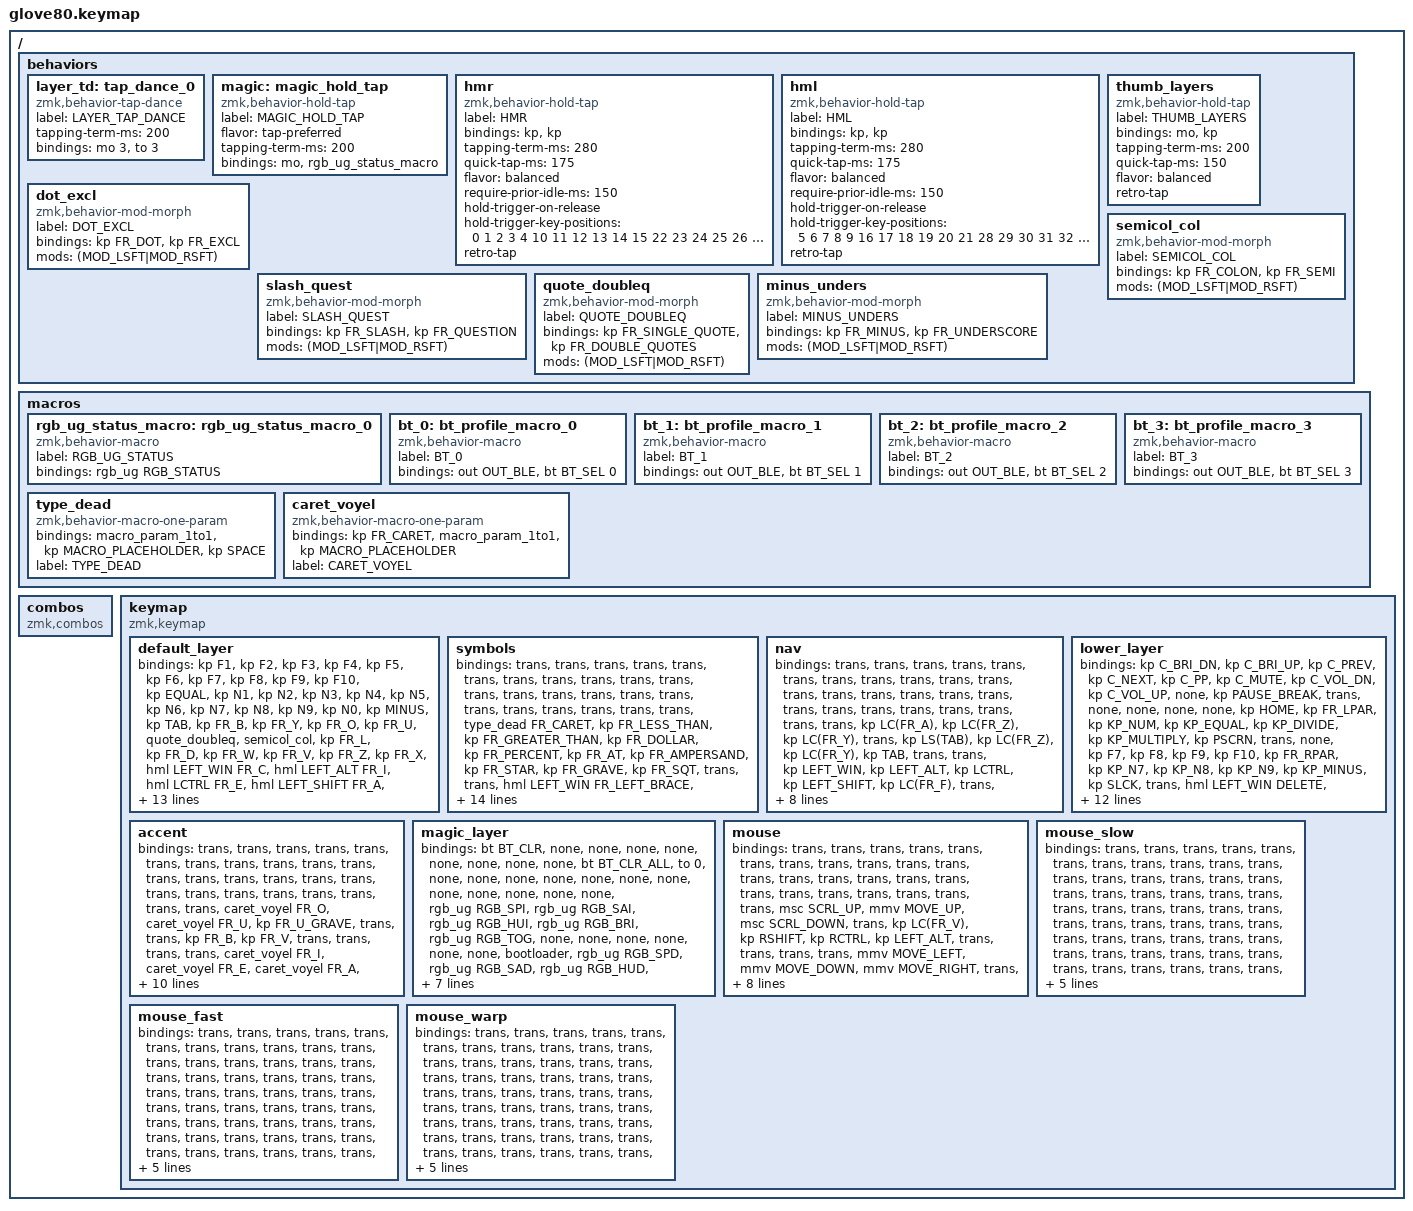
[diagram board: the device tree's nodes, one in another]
/*
 * Copyright (c) 2020 The ZMK Contributors
 *
 * SPDX-License-Identifier: MIT
 */

#include <behaviors.dtsi>
#include <dt-bindings/zmk/bt.h>
#include <dt-bindings/zmk/keys.h>
#include <dt-bindings/zmk/outputs.h>
#include <dt-bindings/zmk/pointing.h>
#include <dt-bindings/zmk/rgb.h>
#include "keys_fr_belgian.h"

#define HYPER LC(LS(LG(LALT)))

// layers

#define DEFAULT 0
#define SYMBOLS  1
#define NAV 2
#define LOWER 3
#define ACCENT 4
#define MAGIC 5
#define MOUSE 6
#define MOUSE_SLOW 7
#define MOUSE_FAST 8
#define MOUSE_WARP 9
#define TYPING 10

#include "mouse.dtsi"

/ {
    behaviors {
        // For the "layer" key, it'd nice to be able to use it as either a shift or a toggle.
        // Configure it as a tap dance, so the first tap (or hold) is a &mo and the second tap is a &to

        layer_td: tap_dance_0 {
            compatible = "zmk,behavior-tap-dance";
            label = "LAYER_TAP_DANCE";
            #binding-cells = <0>;
            tapping-term-ms = <200>;
            bindings = <&mo 3>, <&to 3>;
        };

        magic: magic_hold_tap {
            compatible = "zmk,behavior-hold-tap";
            label = "MAGIC_HOLD_TAP";
            #binding-cells = <2>;
            flavor = "tap-preferred";
            tapping-term-ms = <200>;
            bindings = <&mo>, <&rgb_ug_status_macro>;
        };

        hmr: hmr {
            compatible = "zmk,behavior-hold-tap";
            label = "HMR";
            bindings = <&kp>, <&kp>;

            #binding-cells = <2>;
            tapping-term-ms = <280>;
            quick-tap-ms = <175>;
            flavor = "balanced";
            require-prior-idle-ms = <150>;
            hold-trigger-on-release;
            hold-trigger-key-positions = <0 1 2 3 4 10 11 12 13 14 15 22 23 24 25 26 27 34 35 36 37 38 39 46 47 48 49 50 51 52 53 54 64 65 66 67 68 69 70 71 55 56 57 74 73 72>;
            retro-tap;
        };

        hml: hml {
            compatible = "zmk,behavior-hold-tap";
            label = "HML";
            bindings = <&kp>, <&kp>;

            #binding-cells = <2>;
            tapping-term-ms = <280>;
            quick-tap-ms = <175>;
            flavor = "balanced";
            require-prior-idle-ms = <150>;
            hold-trigger-on-release;
            hold-trigger-key-positions = <5 6 7 8 9 16 17 18 19 20 21 28 29 30 31 32 33 40 41 42 43 44 45 57 58 59 60 61 62 63 73 74 75 76 77 78 79 72 55 56 54 71 70 69 52 53>;
            retro-tap;
        };

        thumb_layers: thumb_layers {
            compatible = "zmk,behavior-hold-tap";
            label = "THUMB_LAYERS";
            bindings = <&mo>, <&kp>;

            #binding-cells = <2>;
            tapping-term-ms = <200>;
            quick-tap-ms = <150>;
            flavor = "balanced";
            retro-tap;
        };

        dot_excl: dot_excl {
            compatible = "zmk,behavior-mod-morph";
            label = "DOT_EXCL";
            bindings = <&kp FR_DOT>, <&kp FR_EXCL>;

            #binding-cells = <0>;
            mods = <(MOD_LSFT|MOD_RSFT)>;
        };

        semicol_col: semicol_col {
            compatible = "zmk,behavior-mod-morph";
            label = "SEMICOL_COL";
            bindings = <&kp FR_COLON>, <&kp FR_SEMI>;

            #binding-cells = <0>;
            mods = <(MOD_LSFT|MOD_RSFT)>;
        };

        slash_quest: slash_quest {
            compatible = "zmk,behavior-mod-morph";
            label = "SLASH_QUEST";
            bindings = <&kp FR_SLASH>, <&kp FR_QUESTION>;

            #binding-cells = <0>;
            mods = <(MOD_LSFT|MOD_RSFT)>;
        };

        quote_doubleq: quote_doubleq {
            compatible = "zmk,behavior-mod-morph";
            label = "QUOTE_DOUBLEQ";
            bindings = <&kp FR_SINGLE_QUOTE>, <&kp FR_DOUBLE_QUOTES>;

            #binding-cells = <0>;
            mods = <(MOD_LSFT|MOD_RSFT)>;
        };

        minus_unders: minus_unders {
            compatible = "zmk,behavior-mod-morph";
            label = "MINUS_UNDERS";
            bindings = <&kp FR_MINUS>, <&kp FR_UNDERSCORE>;

            #binding-cells = <0>;
            mods = <(MOD_LSFT|MOD_RSFT)>;
        };
    };

    macros {
        rgb_ug_status_macro: rgb_ug_status_macro_0 {
            label = "RGB_UG_STATUS";
            compatible = "zmk,behavior-macro";
            #binding-cells = <0>;
            bindings = <&rgb_ug RGB_STATUS>;
        };

        bt_0: bt_profile_macro_0 {
            label = "BT_0";
            compatible = "zmk,behavior-macro";
            #binding-cells = <0>;
            bindings = <&out OUT_BLE &bt BT_SEL 0>;
        };

        bt_1: bt_profile_macro_1 {
            label = "BT_1";
            compatible = "zmk,behavior-macro";
            #binding-cells = <0>;
            bindings = <&out OUT_BLE &bt BT_SEL 1>;
        };

        bt_2: bt_profile_macro_2 {
            label = "BT_2";
            compatible = "zmk,behavior-macro";
            #binding-cells = <0>;
            bindings = <&out OUT_BLE &bt BT_SEL 2>;
        };

        bt_3: bt_profile_macro_3 {
            label = "BT_3";
            compatible = "zmk,behavior-macro";
            #binding-cells = <0>;
            bindings = <&out OUT_BLE &bt BT_SEL 3>;
        };

        type_dead: type_dead {
            compatible = "zmk,behavior-macro-one-param";
            #binding-cells = <1>;
            bindings = <&macro_param_1to1 &kp MACRO_PLACEHOLDER &kp SPACE>;
            label = "TYPE_DEAD";
        };

        caret_voyel: caret_voyel {
            compatible = "zmk,behavior-macro-one-param";
            #binding-cells = <1>;
            bindings = <&kp FR_CARET &macro_param_1to1 &kp MACRO_PLACEHOLDER>;
            label = "CARET_VOYEL";
        };
    };

    combos { compatible = "zmk,combos"; };

    keymap {
        compatible = "zmk,keymap";

        default_layer {
            // ---------------------------------------------------------------------------------------------------------------------------------
            // |  F1   |  F2 |  F3 |  F4  |  F5  |                                                               |  F6   |  F7   |  F8  |   F9  |  F10 |
            // |  =    |  1  |  2  |  3   |  4   |  5   |                                                 |  6   |   7   |   8   |  9   |   0   |   -  |
            // |  TAB  |  Q  |  W  |  E   |  R   |  T   |                                                 |  Y   |   U   |   I   |  O   |   P   |   \  |
            // |  ESC  |  A  |  S  |  D   |  F   |  G   |                                                 |  H   |   J   |   K   |  L   |   ;   |   '  |
            // |   `   |  Z  |  X  |  C   |  V   |  B   | LSHFT | LCTRL | LOWER | | LGUI  | RCTRL | RSHFT |  N   |   M   |   ,   |  .   |   /   | PGUP |
            // | MAGIC | HOME| END | LEFT | RIGHT|      | BSPC  | DEL   | LALT  | | RALT  | RET   | SPACE |      |  UP   | DOWN  |  [   |   ]   | PGDN |

            bindings = <
&kp F1      &kp F2              &kp F3              &kp F4           &kp F5                                                                                                                                                                           &kp F6           &kp F7           &kp F8              &kp F9               &kp F10
&kp EQUAL   &kp N1              &kp N2              &kp N3           &kp N4                &kp N5                                                                                                                                       &kp N6        &kp N7           &kp N8           &kp N9              &kp N0               &kp MINUS
&kp TAB     &kp FR_B            &kp FR_Y            &kp FR_O         &kp FR_U              &quote_doubleq                                                                                                                               &semicol_col  &kp FR_L         &kp FR_D         &kp FR_W            &kp FR_V             &kp FR_Z
&kp FR_X    &hml LEFT_WIN FR_C  &hml LEFT_ALT FR_I  &hml LCTRL FR_E  &hml LEFT_SHIFT FR_A  &kp FR_COMMA                                                                                                                                 &dot_excl     &hmr RSHFT FR_H  &hmr RCTRL FR_T  &hmr LEFT_ALT FR_S  &hmr RIGHT_WIN FR_N  &kp FR_Q
&kp GRAVE   &kp FR_G            &sl 4               &kp FR_J         &kp FR_K              &minus_unders   &kp ESCAPE                 &kp K_CALC              &kp LS(LG(FR_S))  &caps_word  &kp BACKSPACE        &kp RET                &slash_quest  &kp FR_R         &kp FR_M         &kp FR_F            &kp FR_P             &kp PG_UP
&magic 5 0  &none               &kp END             &kp LEFT         &tog 2                                &thumb_layers 2 BACKSPACE  &thumb_layers 3 DELETE  &kp LALT          &kp RALT    &thumb_layers 6 TAB  &thumb_layers 1 SPACE                &none            &caps_word       &kp CAPSLOCK        &none                &kp PG_DN
            >;
        };

        symbols {
            bindings = <
&trans  &trans                       &trans                             &trans                           &trans                                                                                                            &trans                    &trans               &trans                  &trans                 &trans
&trans  &trans                       &trans                             &trans                           &trans                          &trans                                                          &trans            &trans                    &trans               &trans                  &trans                 &trans
&trans  &type_dead FR_CARET          &kp FR_LESS_THAN                   &kp FR_GREATER_THAN              &kp FR_DOLLAR                   &kp FR_PERCENT                                                  &kp FR_AT         &kp FR_AMPERSAND          &kp FR_STAR          &kp FR_GRAVE            &kp FR_SQT             &trans
&trans  &hml LEFT_WIN FR_LEFT_BRACE  &hml LEFT_ALT FR_LEFT_PARENTHESIS  &hml LCTRL FR_RIGHT_PARENTHESIS  &hml LEFT_SHIFT FR_RIGHT_BRACE  &kp FR_SLASH                                                    &kp FR_BACKSLASH  &hmr RIGHT_SHIFT FR_PLUS  &hmr RCTRL FR_MINUS  &hmr LEFT_ALT FR_EQUAL  &hmr RIGHT_WIN FR_DQT  &trans
&trans  &type_dead FR_TILDE          &kp FR_LEFT_BRACKET                &kp FR_RIGHT_BRACKET             &kp FR_UNDER                    &kp FR_HASH     &trans  &trans  &trans  &trans  &trans  &trans  &kp FR_PIPE       &kp FR_EXCLAMATION        &kp FR_SEMICOLON     &kp FR_COLON            &kp FR_EURO            &trans
&trans  &trans                       &trans                             &trans                           &trans                                          &trans  &trans  &trans  &trans  &trans  &trans                    &trans                    &trans               &trans                  &trans                 &trans
            >;
        };

        nav {
            bindings = <
&trans        &trans        &trans        &trans        &trans                                                                                &trans          &trans        &trans          &trans     &trans
&trans        &trans        &trans        &trans        &trans          &trans                                                        &trans  &trans          &trans        &trans          &trans     &trans
&trans        &trans        &trans        &kp LC(FR_A)  &kp LC(FR_Z)    &kp LC(FR_Y)                                                  &trans  &kp LS(TAB)     &kp LC(FR_Z)  &kp LC(FR_Y)    &kp TAB    &trans
&trans        &kp LEFT_WIN  &kp LEFT_ALT  &kp LCTRL     &kp LEFT_SHIFT  &kp LC(FR_F)                                                  &trans  &kp LEFT_ARROW  &kp UP        &kp DOWN_ARROW  &kp RIGHT  &trans
&kp LC(FR_L)  &kp LG(FR_V)  &kp LC(FR_X)  &kp LC(FR_C)  &kp LC(FR_V)    &none         &trans  &trans  &trans  &trans  &trans  &trans  &trans  &kp HOME        &kp PAGE_UP   &kp PAGE_DOWN   &kp END    &trans
&trans        &trans        &trans        &trans        &trans                        &trans  &trans  &trans  &trans  &trans  &trans          &trans          &trans        &trans          &trans     &trans
            >;
        };

        lower_layer {
            bindings = <
&kp C_BRI_DN  &kp C_BRI_UP          &kp C_PREV        &kp C_NEXT     &kp C_PP                                                                                &kp C_MUTE         &kp C_VOL_DN      &kp C_VOL_UP         &none                   &kp PAUSE_BREAK
&trans        &none                 &none             &none          &none           &kp HOME                                                  &kp FR_LPAR   &kp KP_NUM         &kp KP_EQUAL      &kp KP_DIVIDE        &kp KP_MULTIPLY         &kp PSCRN
&trans        &none                 &kp F7            &kp F8         &kp F9          &kp F10                                                   &kp FR_RPAR   &kp KP_N7          &kp KP_N8         &kp KP_N9            &kp KP_MINUS            &kp SLCK
&trans        &hml LEFT_WIN DELETE  &hml LEFT_ALT F4  &hml LCTRL F5  &hml RSHIFT F6  &kp F11                                                   &kp FR_PRCNT  &hmr RSHIFT KP_N4  &hmr RCTRL KP_N5  &hmr LEFT_ALT KP_N6  &hmr RIGHT_WIN KP_PLUS  &none
&trans        &kp K_CMENU           &kp F1            &kp F2         &kp F3          &kp F12   &trans  &trans  &to 0   &trans  &trans  &trans  &kp FR_COMMA  &kp KP_N1          &kp KP_N2         &kp KP_N3            &kp KP_ENTER            &trans
&trans        &kp CAPS              &kp INS           &kp F11        &kp F12                   &trans  &trans  &trans  &trans  &trans  &trans                &kp KP_N0          &kp KP_N0         &kp KP_DOT           &kp KP_ENTER            &trans
            >;
        };

        accent {
            bindings = <
&trans  &trans            &trans             &trans              &trans                                                                                             &trans        &trans            &trans    &trans  &trans
&trans  &trans            &trans             &trans              &trans             &trans                                                                  &trans  &trans        &trans            &trans    &trans  &trans
&trans  &trans            &trans             &caret_voyel FR_O   &caret_voyel FR_U  &kp FR_U_GRAVE                                                          &trans  &trans        &kp FR_B          &kp FR_V  &trans  &trans
&trans  &trans            &caret_voyel FR_I  &caret_voyel FR_E   &caret_voyel FR_A  &kp FR_A_GRAVE                                                          &trans  &kp FR_CARET  &kp LS(FR_CARET)  &kp FR_Z  &trans  &trans
&trans  &kp FR_C_CEDILLA  &kp FR_CARET       &kp FR_E_ACUTE      &kp FR_E_GRAVE     &kp LS(FR_A_GRAVE)  &trans  &trans  &trans  &trans  &trans  &trans      &trans  &trans        &trans            &kp FR_B  &trans  &trans
&trans  &trans            &trans             &kp LS(FR_E_ACUTE)  &trans                                 &trans  &trans  &trans  &trans  &trans  &kp FR_SQT          &trans        &trans            &trans    &trans  &trans
            >;
        };

        magic_layer {
            bindings = <
&bt BT_CLR   &none            &none            &none            &none                                                                                     &none  &none  &none  &none  &bt BT_CLR_ALL
&to 0        &none            &none            &none            &none            &none                                                             &none  &none  &none  &none  &none  &none
&none        &rgb_ug RGB_SPI  &rgb_ug RGB_SAI  &rgb_ug RGB_HUI  &rgb_ug RGB_BRI  &rgb_ug RGB_TOG                                                   &none  &none  &none  &none  &none  &none
&bootloader  &rgb_ug RGB_SPD  &rgb_ug RGB_SAD  &rgb_ug RGB_HUD  &rgb_ug RGB_BRD  &rgb_ug RGB_EFF                                                   &none  &none  &none  &none  &none  &bootloader
&sys_reset   &none            &none            &none            &none            &none            &bt_2  &bt_3  &none         &none  &none  &none  &none  &none  &none  &none  &none  &sys_reset
&none        &none            &none            &none            &none                             &bt_0  &bt_1  &out OUT_USB  &none  &none  &none         &none  &none  &none  &none  &to 0
            >;
        };

        mouse {
            bindings = <
&trans  &trans  &trans          &trans          &trans                                                                                                     &trans      &trans     &trans        &trans  &trans
&trans  &trans  &trans          &trans          &trans           &trans                                                                      &trans        &trans      &trans     &trans        &trans  &trans
&trans  &trans  &msc SCRL_UP    &mmv MOVE_UP    &msc SCRL_DOWN   &trans                                                                      &kp LC(FR_V)  &kp RSHIFT  &kp RCTRL  &kp LEFT_ALT  &trans  &trans
&trans  &trans  &mmv MOVE_LEFT  &mmv MOVE_DOWN  &mmv MOVE_RIGHT  &trans                                                                      &kp LC(FR_C)  &mo 7       &mo 8      &mo 9         &trans  &trans
&trans  &trans  &mkp MB4        &trans          &mkp MB5         &trans  &mkp MCLK  &trans     &trans  &trans  &to 0  &trans                 &trans        &trans      &trans     &trans        &trans  &trans
&trans  &trans  &trans          &trans          &trans                   &mkp LCLK  &mkp RCLK  &trans  &trans  &none  &thumb_layers 0 SPACE                &trans      &trans     &trans        &trans  &trans
            >;
        };

        mouse_slow {
            bindings = <
&trans  &trans  &trans  &trans  &trans                                                                  &trans  &trans  &trans  &trans  &trans
&trans  &trans  &trans  &trans  &trans  &trans                                                  &trans  &trans  &trans  &trans  &trans  &trans
&trans  &trans  &trans  &trans  &trans  &trans                                                  &trans  &trans  &trans  &trans  &trans  &trans
&trans  &trans  &trans  &trans  &trans  &trans                                                  &trans  &trans  &trans  &trans  &trans  &trans
&trans  &trans  &trans  &trans  &trans  &trans  &trans  &trans  &trans  &trans  &trans  &trans  &trans  &trans  &trans  &trans  &trans  &trans
&trans  &trans  &trans  &trans  &trans          &trans  &trans  &trans  &trans  &trans  &trans          &trans  &trans  &trans  &trans  &trans
            >;
        };

        mouse_fast {
            bindings = <
&trans  &trans  &trans  &trans  &trans                                                                  &trans  &trans  &trans  &trans  &trans
&trans  &trans  &trans  &trans  &trans  &trans                                                  &trans  &trans  &trans  &trans  &trans  &trans
&trans  &trans  &trans  &trans  &trans  &trans                                                  &trans  &trans  &trans  &trans  &trans  &trans
&trans  &trans  &trans  &trans  &trans  &trans                                                  &trans  &trans  &trans  &trans  &trans  &trans
&trans  &trans  &trans  &trans  &trans  &trans  &trans  &trans  &trans  &trans  &trans  &trans  &trans  &trans  &trans  &trans  &trans  &trans
&trans  &trans  &trans  &trans  &trans          &trans  &trans  &trans  &trans  &trans  &trans          &trans  &trans  &trans  &trans  &trans
            >;
        };

        mouse_warp {
            bindings = <
&trans  &trans  &trans  &trans  &trans                                                                  &trans  &trans  &trans  &trans  &trans
&trans  &trans  &trans  &trans  &trans  &trans                                                  &trans  &trans  &trans  &trans  &trans  &trans
&trans  &trans  &trans  &trans  &trans  &trans                                                  &trans  &trans  &trans  &trans  &trans  &trans
&trans  &trans  &trans  &trans  &trans  &trans                                                  &trans  &trans  &trans  &trans  &trans  &trans
&trans  &trans  &trans  &trans  &trans  &trans  &trans  &trans  &trans  &trans  &trans  &trans  &trans  &trans  &trans  &trans  &trans  &trans
&trans  &trans  &trans  &trans  &trans          &trans  &trans  &trans  &trans  &trans  &trans          &trans  &trans  &trans  &trans  &trans
            >;
        };
    };
};
